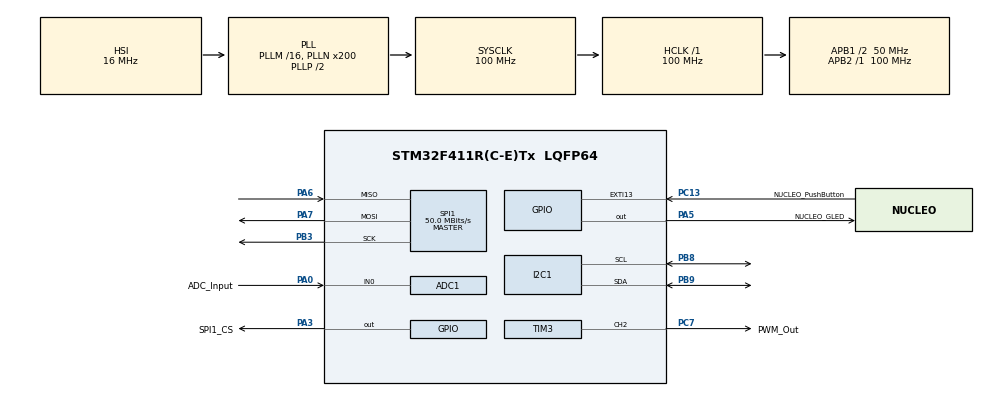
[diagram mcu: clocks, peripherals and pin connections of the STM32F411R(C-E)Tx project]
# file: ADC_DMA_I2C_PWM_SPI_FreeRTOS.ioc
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ADC1.Channel-0\#ChannelRegularConversion=ADC_CHANNEL_0
ADC1.ContinuousConvMode=ENABLE
ADC1.DMAContinuousRequests=ENABLE
ADC1.NbrOfConversionFlag=1
ADC1.Rank-0\#ChannelRegularConversion=1
ADC1.SamplingTime-0\#ChannelRegularConversion=ADC_SAMPLETIME_15CYCLES
ADC1.master=1
Dma.ADC1.0.Direction=DMA_PERIPH_TO_MEMORY
Dma.ADC1.0.FIFOMode=DMA_FIFOMODE_DISABLE
Dma.ADC1.0.Instance=DMA2_Stream0
Dma.ADC1.0.MemDataAlignment=DMA_MDATAALIGN_HALFWORD
Dma.ADC1.0.MemInc=DMA_MINC_ENABLE
Dma.ADC1.0.Mode=DMA_CIRCULAR
Dma.ADC1.0.PeriphDataAlignment=DMA_PDATAALIGN_HALFWORD
Dma.ADC1.0.PeriphInc=DMA_PINC_DISABLE
Dma.ADC1.0.Priority=DMA_PRIORITY_HIGH
Dma.Request0=ADC1
Dma.Request1=TIM3_CH2
Dma.TIM3_CH2.1.Direction=DMA_MEMORY_TO_PERIPH
Dma.TIM3_CH2.1.FIFOMode=DMA_FIFOMODE_DISABLE
Dma.TIM3_CH2.1.Instance=DMA1_Stream5
Dma.TIM3_CH2.1.MemDataAlignment=DMA_MDATAALIGN_HALFWORD
Dma.TIM3_CH2.1.MemInc=DMA_MINC_ENABLE
Dma.TIM3_CH2.1.Mode=DMA_CIRCULAR
Dma.TIM3_CH2.1.PeriphDataAlignment=DMA_PDATAALIGN_HALFWORD
Dma.TIM3_CH2.1.PeriphInc=DMA_PINC_DISABLE
Dma.TIM3_CH2.1.Priority=DMA_PRIORITY_MEDIUM
FREERTOS.INCLUDE_pcTaskGetTaskName=1
FREERTOS.INCLUDE_uxTaskGetStackHighWaterMark2=1
FREERTOS.INCLUDE_vTaskCleanUpResources=1
FREERTOS.INCLUDE_xEventGroupSetBitFromISR=1
FREERTOS.INCLUDE_xSemaphoreGetMutexHolder=1
FREERTOS.INCLUDE_xTaskAbortDelay=1
FREERTOS.INCLUDE_xTaskGetHandle=1
FREERTOS.Tasks01=defaultTask,24,128,StartDefaultTask,Default,NULL,Dynamic,NULL,NULL
FREERTOS.configTIMER_TASK_STACK_DEPTH=512
FREERTOS.configTOTAL_HEAP_SIZE=24576
FREERTOS.configUSE_IDLE_HOOK=1
FREERTOS.configUSE_MALLOC_FAILED_HOOK=1
Mcu.Family=STM32F4
Mcu.Name=STM32F411R(C-E)Tx
Mcu.Package=LQFP64
NVIC.DMA1_Stream5_IRQn=true\:5\:0\:false\:false\:true\:true\:false\:true
NVIC.DMA2_Stream0_IRQn=true\:5\:0\:false\:false\:true\:true\:false\:true
NVIC.EXTI15_10_IRQn=true\:6\:0\:true\:false\:true\:true\:true\:true
NVIC.I2C1_EV_IRQn=true\:6\:0\:true\:false\:true\:true\:true\:true
NVIC.PriorityGroup=NVIC_PRIORITYGROUP_4
NVIC.SPI1_IRQn=true\:6\:0\:true\:false\:true\:true\:true\:true
NVIC.TIM1_BRK_TIM9_IRQn=true\:7\:0\:true\:false\:true\:true\:true\:true
NVIC.TIM2_IRQn=true\:0\:0\:false\:false\:true\:false\:false\:true
NVIC.TIM5_IRQn=true\:7\:0\:true\:false\:true\:true\:true\:true
NVIC.TimeBase=TIM2_IRQn
NVIC.TimeBaseIP=TIM2
PA0-WKUP.GPIO_Label=ADC_Input
PA0-WKUP.Signal=ADCx_IN0
PA13.Mode=Serial_Wire
PA13.Signal=SYS_JTMS-SWDIO
PA14.Mode=Serial_Wire
PA14.Signal=SYS_JTCK-SWCLK
PA3.GPIO_Label=SPI1_CS
PA3.GPIO_Speed=GPIO_SPEED_FREQ_HIGH
PA3.Signal=GPIO_Output
PA5.GPIO_Label=NUCLEO_GLED
PA5.GPIO_Speed=GPIO_SPEED_FREQ_HIGH
PA5.Signal=GPIO_Output
PA6.Mode=Full_Duplex_Master
PA6.Signal=SPI1_MISO
PA7.Mode=Full_Duplex_Master
PA7.Signal=SPI1_MOSI
PB3.Mode=Full_Duplex_Master
PB3.Signal=SPI1_SCK
PB8.Mode=I2C
PB8.Signal=I2C1_SCL
PB9.Mode=I2C
PB9.Signal=I2C1_SDA
PC13-ANTI_TAMP.GPIO_Label=NUCLEO_PushButton
PC13-ANTI_TAMP.Signal=GPXTI13
PC7.GPIO_Label=PWM_Out
PC7.GPIO_Speed=GPIO_SPEED_FREQ_HIGH
PC7.Signal=S_TIM3_CH2
ProjectManager.HeapSize=0x200
ProjectManager.StackSize=0x900
ProjectManager.TargetToolchain=MDK-ARM V5.27
RCC.48MHZClocksFreq_Value=50000000
RCC.AHBFreq_Value=100000000
RCC.APB1CLKDivider=RCC_HCLK_DIV2
RCC.APB1Freq_Value=50000000
RCC.APB1TimFreq_Value=100000000
RCC.APB2Freq_Value=100000000
RCC.APB2TimFreq_Value=100000000
RCC.CortexFreq_Value=100000000
RCC.HCLKFreq_Value=100000000
RCC.HSE_VALUE=25000000
RCC.HSI_VALUE=16000000
RCC.LSE_VALUE=32768
RCC.PLLN=200
RCC.SYSCLKFreq_VALUE=100000000
RCC.SYSCLKSource=RCC_SYSCLKSOURCE_PLLCLK
RCC.VCOOutputFreq_Value=200000000
SH.ADCx_IN0.0=ADC1_IN0,IN0
SH.S_TIM3_CH2.0=TIM3_CH2,PWM Generation2 CH2
SPI1.CLKPhase=SPI_PHASE_2EDGE
SPI1.CalculateBaudRate=50.0 MBits/s
SPI1.Direction=SPI_DIRECTION_2LINES
SPI1.Mode=SPI_MODE_MASTER
SPI1.VirtualType=VM_MASTER
TIM3.Channel-PWM\ Generation2\ CH2=TIM_CHANNEL_2
VP_FREERTOS_VS_CMSIS_V2.Mode=CMSIS_V2
VP_SYS_VS_tim2.Mode=TIM2
VP_TIM5_VS_ClockSourceINT.Mode=Internal
VP_TIM9_VS_ClockSourceINT.Mode=Internal
board=custom

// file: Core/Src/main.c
/* USER CODE BEGIN Header */
/**
  ******************************************************************************
  * @file           : main.c
  * @brief          : Main program body
  ******************************************************************************
  * @attention
  *
  * <h2><center>&copy; Copyright (c) 2021 STMicroelectronics.
  * All rights reserved.</center></h2>
  *
  * This software component is licensed by ST under Ultimate Liberty license
  * SLA0044, the "License"; You may not use this file except in compliance with
  * the License. You may obtain a copy of the License at:
  *                             www.st.com/SLA0044
  *
  ******************************************************************************
  */
/* USER CODE END Header */
#include "main.h"
#include "cmsis_os.h"

#include "FreeRTOS.h"
#include "task.h"

#include "freertos_impl.h"

/* These variables hold the remaining stack size of FreeRTOS tasks from where
   they were respectively called from. */
extern UBaseType_t TaskMCUPB_RSS;
extern UBaseType_t TaskADCPWM_RSS;
extern UBaseType_t TaskMCULED_RSS;

/*--- Used onboard peripherals ---*/
ADC_HandleTypeDef hadc1;
DMA_HandleTypeDef hdma_adc1;
I2C_HandleTypeDef hi2c1;
SPI_HandleTypeDef hspi1;
TIM_HandleTypeDef htim3;
TIM_HandleTypeDef htim5;
TIM_HandleTypeDef htim9;
DMA_HandleTypeDef hdma_tim3_ch2;

/* Definitions for defaultTask */
osThreadId_t defaultTaskHandle;
const osThreadAttr_t defaultTask_attributes = {
  .name = "defaultTask",
  .stack_size = 128 * 4,
  .priority = (osPriority_t) osPriorityNormal,
};

void SystemClock_Config(void);
static void MX_GPIO_Init(void);
static void MX_DMA_Init(void);
static void MX_ADC1_Init(void);
static void MX_I2C1_Init(void);
static void MX_SPI1_Init(void);
static void MX_TIM3_Init(void);
static void MX_TIM5_Init(void);
static void MX_TIM9_Init(void);
void StartDefaultTask(void *argument);

int main(void)
{
  /* MCU Configuration--------------------------------------------------------*/
  /* Reset of all peripherals, Initializes the Flash interface and the Systick. */
  HAL_Init();

  /* Configure the system clock */
  SystemClock_Config();

  /* Initialize all configured peripherals */
  MX_GPIO_Init();
  MX_DMA_Init();
  MX_ADC1_Init();
  MX_I2C1_Init();
  MX_SPI1_Init();
  MX_TIM3_Init();
  MX_TIM5_Init();
  MX_TIM9_Init();

  /* Init scheduler */
  osKernelInitialize();

  /* USER CODE BEGIN RTOS_MUTEX */
	FRTOS_Init_Mutex();

  /* USER CODE BEGIN RTOS_TIMERS */
	FRTOS_Init_SWTimers();

  /* USER CODE BEGIN RTOS_QUEUES */

  /* Create the thread(s) */
	FRTOS_Init_Tasks();

  /* Start scheduler */
  osKernelStart();

  /* We should never get here as control is now taken by the scheduler */
  /* Infinite loop */
  while (1)
  {

  }
}

void SystemClock_Config(void)
{
  RCC_OscInitTypeDef RCC_OscInitStruct = {0};
  RCC_ClkInitTypeDef RCC_ClkInitStruct = {0};

  /** Configure the main internal regulator output voltage
  */
  __HAL_RCC_PWR_CLK_ENABLE();
  __HAL_PWR_VOLTAGESCALING_CONFIG(PWR_REGULATOR_VOLTAGE_SCALE1);
  /** Initializes the RCC Oscillators according to the specified parameters
  * in the RCC_OscInitTypeDef structure.
  */
  RCC_OscInitStruct.OscillatorType = RCC_OSCILLATORTYPE_HSI;
  RCC_OscInitStruct.HSIState = RCC_HSI_ON;
  RCC_OscInitStruct.HSICalibrationValue = RCC_HSICALIBRATION_DEFAULT;
  RCC_OscInitStruct.PLL.PLLState = RCC_PLL_ON;
  RCC_OscInitStruct.PLL.PLLSource = RCC_PLLSOURCE_HSI;
  RCC_OscInitStruct.PLL.PLLM = 16;
  RCC_OscInitStruct.PLL.PLLN = 200;
  RCC_OscInitStruct.PLL.PLLP = RCC_PLLP_DIV2;
  RCC_OscInitStruct.PLL.PLLQ = 4;
  if (HAL_RCC_OscConfig(&RCC_OscInitStruct) != HAL_OK)
  {
    Error_Handler();
  }
  /** Initializes the CPU, AHB and APB buses clocks
  */
  RCC_ClkInitStruct.ClockType = RCC_CLOCKTYPE_HCLK|RCC_CLOCKTYPE_SYSCLK
                              |RCC_CLOCKTYPE_PCLK1|RCC_CLOCKTYPE_PCLK2;
  RCC_ClkInitStruct.SYSCLKSource = RCC_SYSCLKSOURCE_PLLCLK;
  RCC_ClkInitStruct.AHBCLKDivider = RCC_SYSCLK_DIV1;
  RCC_ClkInitStruct.APB1CLKDivider = RCC_HCLK_DIV2;
  RCC_ClkInitStruct.APB2CLKDivider = RCC_HCLK_DIV1;

  if (HAL_RCC_ClockConfig(&RCC_ClkInitStruct, FLASH_LATENCY_3) != HAL_OK)
  {
    Error_Handler();
  }
}

static void MX_ADC1_Init(void)
{

  ADC_ChannelConfTypeDef sConfig = {0};

  /** Configure the global features of the ADC (Clock, Resolution, Data Alignment and number of conversion)
  */
  hadc1.Instance = ADC1;
  hadc1.Init.ClockPrescaler = ADC_CLOCK_SYNC_PCLK_DIV4;
  hadc1.Init.Resolution = ADC_RESOLUTION_12B;
  hadc1.Init.ScanConvMode = DISABLE;
  hadc1.Init.ContinuousConvMode = ENABLE;
  hadc1.Init.DiscontinuousConvMode = DISABLE;
  hadc1.Init.ExternalTrigConvEdge = ADC_EXTERNALTRIGCONVEDGE_NONE;
  hadc1.Init.ExternalTrigConv = ADC_SOFTWARE_START;
  hadc1.Init.DataAlign = ADC_DATAALIGN_RIGHT;
  hadc1.Init.NbrOfConversion = 1;
  hadc1.Init.DMAContinuousRequests = ENABLE;
  hadc1.Init.EOCSelection = ADC_EOC_SINGLE_CONV;
  if (HAL_ADC_Init(&hadc1) != HAL_OK)
  {
    Error_Handler();
  }
  /** Configure for the selected ADC regular channel its corresponding rank in the sequencer and its sample time.
  */
  sConfig.Channel = ADC_CHANNEL_0;
  sConfig.Rank = 1;
  sConfig.SamplingTime = ADC_SAMPLETIME_480CYCLES; //ADC_SAMPLETIME_15CYCLES;
  if (HAL_ADC_ConfigChannel(&hadc1, &sConfig) != HAL_OK)
  {
    Error_Handler();
  }

}

static void MX_I2C1_Init(void)
{

  hi2c1.Instance = I2C1;
  hi2c1.Init.ClockSpeed = 100000;
  hi2c1.Init.DutyCycle = I2C_DUTYCYCLE_2;
  hi2c1.Init.OwnAddress1 = 0;
  hi2c1.Init.AddressingMode = I2C_ADDRESSINGMODE_7BIT;
  hi2c1.Init.DualAddressMode = I2C_DUALADDRESS_DISABLE;
  hi2c1.Init.OwnAddress2 = 0;
  hi2c1.Init.GeneralCallMode = I2C_GENERALCALL_DISABLE;
  hi2c1.Init.NoStretchMode = I2C_NOSTRETCH_DISABLE;
  if (HAL_I2C_Init(&hi2c1) != HAL_OK)
  {
    Error_Handler();
  }

}

static void MX_SPI1_Init(void)
{

  /* SPI1 parameter configuration*/
  hspi1.Instance = SPI1;
  hspi1.Init.Mode = SPI_MODE_MASTER;
  hspi1.Init.Direction = SPI_DIRECTION_2LINES;
  hspi1.Init.DataSize = SPI_DATASIZE_8BIT;
  hspi1.Init.CLKPolarity = SPI_POLARITY_LOW;
  hspi1.Init.CLKPhase = SPI_PHASE_2EDGE;
  hspi1.Init.NSS = SPI_NSS_SOFT;
  hspi1.Init.BaudRatePrescaler = SPI_BAUDRATEPRESCALER_2;
  hspi1.Init.FirstBit = SPI_FIRSTBIT_MSB;
  hspi1.Init.TIMode = SPI_TIMODE_DISABLE;
  hspi1.Init.CRCCalculation = SPI_CRCCALCULATION_DISABLE;
  hspi1.Init.CRCPolynomial = 10;
  if (HAL_SPI_Init(&hspi1) != HAL_OK)
  {
    Error_Handler();
  }

}

static void MX_TIM3_Init(void)
{
  /* USER CODE BEGIN TIM3_Init 0 */
	/* Need to manually enable TIM3 Bus Clock to allow modifying the TIM3 Peripheral
	   Registers as it wasn't included in CubeMX generated code */
	__HAL_RCC_TIM3_CLK_ENABLE();

  /* USER CODE END TIM3_Init 0 */
	TIM_ClockConfigTypeDef sClockSourceConfig = {0};
  TIM_MasterConfigTypeDef sMasterConfig = {0};
  TIM_OC_InitTypeDef sConfigOC = {0};

  htim3.Instance = TIM3;
  htim3.Init.Prescaler = 9;
  htim3.Init.CounterMode = TIM_COUNTERMODE_UP;
  htim3.Init.Period = 999;
  htim3.Init.ClockDivision = TIM_CLOCKDIVISION_DIV1;
  htim3.Init.AutoReloadPreload = TIM_AUTORELOAD_PRELOAD_DISABLE;
  if (HAL_TIM_Base_Init(&htim3) != HAL_OK)
  {
    Error_Handler();
  }
  sClockSourceConfig.ClockSource = TIM_CLOCKSOURCE_INTERNAL;
  if (HAL_TIM_ConfigClockSource(&htim3, &sClockSourceConfig) != HAL_OK)
  {
    Error_Handler();
  }
  if (HAL_TIM_PWM_Init(&htim3) != HAL_OK)
  {
    Error_Handler();
  }
  sMasterConfig.MasterOutputTrigger = TIM_TRGO_RESET;
  sMasterConfig.MasterSlaveMode = TIM_MASTERSLAVEMODE_DISABLE;
  if (HAL_TIMEx_MasterConfigSynchronization(&htim3, &sMasterConfig) != HAL_OK)
  {
    Error_Handler();
  }
  sConfigOC.OCMode = TIM_OCMODE_PWM1;
  sConfigOC.Pulse = 0;
  sConfigOC.OCPolarity = TIM_OCPOLARITY_HIGH;
  sConfigOC.OCFastMode = TIM_OCFAST_DISABLE;
  if (HAL_TIM_PWM_ConfigChannel(&htim3, &sConfigOC, TIM_CHANNEL_2) != HAL_OK)
  {
    Error_Handler();
  }

  /* USER CODE BEGIN TIM3_Init 2 */
	/* Need to manually add the configuration and initialization of DMA peripheral
     to TIM3 as it wasn't included in CubeMX generated code	*/
	HAL_TIM_PWM_MspInit(&htim3);
  /* USER CODE END TIM3_Init 2 */

  HAL_TIM_MspPostInit(&htim3);
}

static void MX_TIM5_Init(void)
{

  TIM_ClockConfigTypeDef sClockSourceConfig = {0};
  TIM_MasterConfigTypeDef sMasterConfig = {0};

  htim5.Instance = TIM5;
  htim5.Init.Prescaler = 0;
  htim5.Init.CounterMode = TIM_COUNTERMODE_UP;
  htim5.Init.Period = 4294967295;
  htim5.Init.ClockDivision = TIM_CLOCKDIVISION_DIV1;
  htim5.Init.AutoReloadPreload = TIM_AUTORELOAD_PRELOAD_DISABLE;
  if (HAL_TIM_Base_Init(&htim5) != HAL_OK)
  {
    Error_Handler();
  }
  sClockSourceConfig.ClockSource = TIM_CLOCKSOURCE_INTERNAL;
  if (HAL_TIM_ConfigClockSource(&htim5, &sClockSourceConfig) != HAL_OK)
  {
    Error_Handler();
  }
  sMasterConfig.MasterOutputTrigger = TIM_TRGO_RESET;
  sMasterConfig.MasterSlaveMode = TIM_MASTERSLAVEMODE_DISABLE;
  if (HAL_TIMEx_MasterConfigSynchronization(&htim5, &sMasterConfig) != HAL_OK)
  {
    Error_Handler();
  }

}

static void MX_TIM9_Init(void)
{

  TIM_ClockConfigTypeDef sClockSourceConfig = {0};

  htim9.Instance = TIM9;
  htim9.Init.Prescaler = 9999;
  htim9.Init.CounterMode = TIM_COUNTERMODE_UP;
  htim9.Init.Period = 9999;
  htim9.Init.ClockDivision = TIM_CLOCKDIVISION_DIV1;
  htim9.Init.AutoReloadPreload = TIM_AUTORELOAD_PRELOAD_DISABLE;
  if (HAL_TIM_Base_Init(&htim9) != HAL_OK)
  {
    Error_Handler();
  }
  sClockSourceConfig.ClockSource = TIM_CLOCKSOURCE_INTERNAL;
  if (HAL_TIM_ConfigClockSource(&htim9, &sClockSourceConfig) != HAL_OK)
  {
    Error_Handler();
  }

}

static void MX_DMA_Init(void)
{

  /* DMA controller clock enable */
  __HAL_RCC_DMA2_CLK_ENABLE();
  __HAL_RCC_DMA1_CLK_ENABLE();

  /* DMA interrupt init */
  /* DMA1_Stream5_IRQn interrupt configuration */
  HAL_NVIC_SetPriority(DMA1_Stream5_IRQn, 5, 2);
  HAL_NVIC_EnableIRQ(DMA1_Stream5_IRQn);
  /* DMA2_Stream0_IRQn interrupt configuration */
  HAL_NVIC_SetPriority(DMA2_Stream0_IRQn, 5, 1);
  HAL_NVIC_EnableIRQ(DMA2_Stream0_IRQn);

}

static void MX_GPIO_Init(void)
{
  GPIO_InitTypeDef GPIO_InitStruct = {0};

  /* GPIO Ports Clock Enable */
  __HAL_RCC_GPIOC_CLK_ENABLE();
  __HAL_RCC_GPIOA_CLK_ENABLE();
  __HAL_RCC_GPIOB_CLK_ENABLE();

  /*Configure GPIO pin Output Level */
  HAL_GPIO_WritePin(GPIOA, SPI1_CS_Pin|NUCLEO_GLED_Pin, GPIO_PIN_RESET);

  /*Configure GPIO pin : NUCLEO_PushButton_Pin */
  GPIO_InitStruct.Pin = NUCLEO_PushButton_Pin;
  GPIO_InitStruct.Mode = GPIO_MODE_IT_RISING;
  GPIO_InitStruct.Pull = GPIO_NOPULL;
  HAL_GPIO_Init(NUCLEO_PushButton_GPIO_Port, &GPIO_InitStruct);

  /*Configure GPIO pins : SPI1_CS_Pin NUCLEO_GLED_Pin */
  GPIO_InitStruct.Pin = SPI1_CS_Pin|NUCLEO_GLED_Pin;
  GPIO_InitStruct.Mode = GPIO_MODE_OUTPUT_PP;
  GPIO_InitStruct.Pull = GPIO_NOPULL;
  GPIO_InitStruct.Speed = GPIO_SPEED_FREQ_HIGH;
  HAL_GPIO_Init(GPIOA, &GPIO_InitStruct);

  /* EXTI interrupt init*/
  HAL_NVIC_SetPriority(EXTI15_10_IRQn, 6, 0);
  HAL_NVIC_EnableIRQ(EXTI15_10_IRQn);

}

void StartDefaultTask(void *argument)
{
  for(;;)
  {
    osDelay(1);
  }
}

void Error_Handler(void)
{
  __disable_irq();
  while (1)
  {
  }
}

/************************ (C) COPYRIGHT STMicroelectronics *****END OF FILE****/

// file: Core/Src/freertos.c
/* USER CODE BEGIN Header */
/**
  ******************************************************************************
  * File Name          : freertos.c
  * Description        : Code for freertos applications
  ******************************************************************************
  * @attention
  *
  * <h2><center>&copy; Copyright (c) 2021 STMicroelectronics.
  * All rights reserved.</center></h2>
  *
  * This software component is licensed by ST under Ultimate Liberty license
  * SLA0044, the "License"; You may not use this file except in compliance with
  * the License. You may obtain a copy of the License at:
  *                             www.st.com/SLA0044
  *
  ******************************************************************************
  */
/* USER CODE END Header */

#include "FreeRTOS.h"
#include "task.h"
#include "main.h"

/* Hook prototypes */
void vApplicationIdleHook(void);
void vApplicationMallocFailedHook(void);

void vApplicationIdleHook( void )
{
   /* vApplicationIdleHook() will only be called if configUSE_IDLE_HOOK is set
   to 1 in FreeRTOSConfig.h. It will be called on each iteration of the idle
   task. It is essential that code added to this hook function never attempts
   to block in any way (for example, call xQueueReceive() with a block time
   specified, or call vTaskDelay()). If the application makes use of the
   vTaskDelete() API function (as this demo application does) then it is also
   important that vApplicationIdleHook() is permitted to return to its calling
   function, because it is the responsibility of the idle task to clean up
   memory allocated by the kernel to any task that has since been deleted. */
}

void vApplicationMallocFailedHook(void)
{
   /* vApplicationMallocFailedHook() will only be called if
   configUSE_MALLOC_FAILED_HOOK is set to 1 in FreeRTOSConfig.h. It is a hook
   function that will get called if a call to pvPortMalloc() fails.
   pvPortMalloc() is called internally by the kernel whenever a task, queue,
   timer or semaphore is created. It is also called by various parts of the
   demo application. If heap_1.c or heap_2.c are used, then the size of the
   heap available to pvPortMalloc() is defined by configTOTAL_HEAP_SIZE in
   FreeRTOSConfig.h, and the xPortGetFreeHeapSize() API function can be used
   to query the size of free heap space that remains (although it does not
   provide information on how the remaining heap might be fragmented). */
}

/************************ (C) COPYRIGHT STMicroelectronics *****END OF FILE****/
